# MCSPI2 register map
Vendor: Texas Instruments
Peripheral module from a debugger description file (folder omap4460).
Registers are 32-bit, read-write, reset 0x0 unless marked. A register's access mark holds for its fields unless they carry their own. Offsets are as the file gives them; lines under a group give offsets from that group; [hi:lo] are bit positions; {n}, {i} and the like mark numbered series; 'fields as' and 'values as' point back to an identical list; <NAME> marks a mode.

## MCSPI2
0x00 MCSPI_HL_REV ro reset not defined — IP Revision Identifier (X.Y.R) Used by software to track features, bugs, and compatibility
  [31:0] REVISION — IP Revision
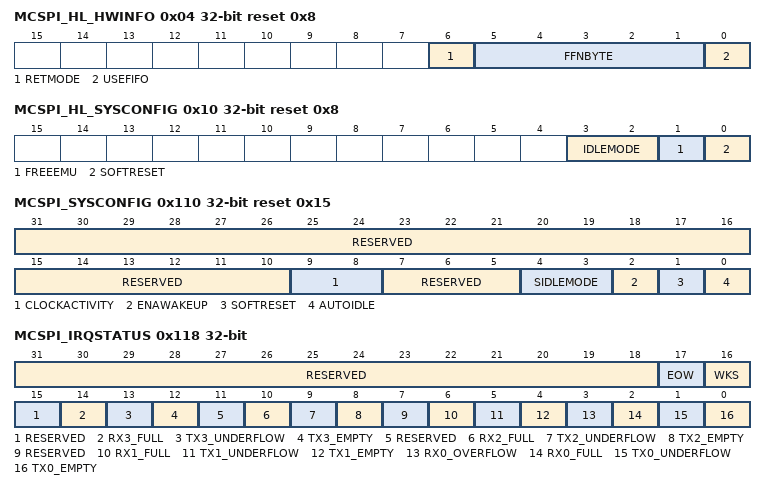
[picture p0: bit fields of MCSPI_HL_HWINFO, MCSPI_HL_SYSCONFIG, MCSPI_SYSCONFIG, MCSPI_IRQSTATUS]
0x04 MCSPI_HL_HWINFO ro reset 0x8 (reset mask 0xFFFFFFBF) — Information about the IP module's hardware configuration, that is, typically the module's HDL generics (if any). Actual field format and encoding is up to the module's designer to decide.
  [6] RETMODE — Retention Mode generic parameter. This bit field indicates whether the retention mode is supported using the pin PIRFFRET. 0x0: Retention mode disabled 0x1: Retention mode enabled
  [5:1] FFNBYTE — FIFO number of byte generic parameter This register defines the value of FFNBYTE generic parameter, only MSB bits from 8 down to 4 are taken into account.
    1=FFNBYTE_1_r (FIFO 16 bytes depth); 2=FFNBYTE_2_r (FIFO 32 bytes depth); 4=FFNBYTE_4_r (FIFO 64 bytes depth); 8=FFNBYTE_8_r (FIFO 128 bytes depth); 16=FFNBYTE_16_r (FIFO 256 bytes depth)
  [0] USEFIFO — Use of a FIFO enable: This bit indicates if a FIFO is integrated within controller design with its management.
    0=USEFIFO_0_r (FIFO not implemented in design); 1=USEFIFO_1_r (FIFO and its management implemented in design with depth defined by FFNBYTE generic)
0x10 MCSPI_HL_SYSCONFIG access per field reset 0x8 — Clock management configuration
  [3:2] IDLEMODE rw — Configuration of the local target state management mode. By definition, target can handle read/write transaction as long as it is out of IDLE state.
    0=Force-idle mode: local target's IDLE state follows (acknowledges) the system's idle requests unconditionally, that is, regardless of the IP module's internal requirements. Backup mode, for debug only.; 1=No-idle mode: local target never enters IDLE state. Backup mode, for debug only.; 2=Smart-idle mode: local target's IDLE state eventually follows (acknowledges) the system's idle requests, depending on the IP module's internal requirements. IP module shall not generate (IRQ- or DMA-request-related) wake-up events.; 3=Smart-idle wake-up-capable mode: local target's IDLE state eventually follows (acknowledges) the system's idle requests, depending on the IP module's internal requirements. IP module may generate (IRQ- or DMA-request-related) wake-up events when in IDLE state. Mode is relevant only if the appropriate IP module 'swake-up' output(s) is (are) implemented.
  [1] FREEEMU rw — Sensitivity to emulation (debug) suspend input signal.
    0=IP module is sensitive to emulation suspend; 1=IP module is not sensitive to emulation suspend
  [0] SOFTRESET rw — Software reset. (Optional)
    0=SOFTRESET_0_w (No action); 0=SOFTRESET_0_r (Reset done, no pending action); 1=SOFTRESET_1_r (Reset (software or other) ongoing); 1=SOFTRESET_1_w (Initiate software reset)
0x100 MCSPI_REVISION ro reset not defined — This register contains the revision number.
  [31:0] REVISION — IP revision
0x110 MCSPI_SYSCONFIG reset 0x15 — This register allows controlling various parameters of the OCP interface.
  [31:10] RESERVED — Reads returns 0
  [9:8] CLOCKACTIVITY — Clocks activity during wake-up mode period
    0=OCP and functional clocks may be switched off; 1=OCP clock is maintained. Functional clock may be switched off.; 2=Functional clock is maintained. OCP clock may be switched off.; 3=OCP and functional clocks are maintained
  [7:5] RESERVED — Reads returns 0
  [4:3] SIDLEMODE — Power management
    0=If an idle request is detected, the McSPI acknowledges it unconditionally and goes in inactive mode. Interrupt, DMA requests and wake-up lines are unconditionally deasserted and the module wake-up capability is deactivated even if the[EnaWakeUp] bit is set.; 1=If an idle request is detected, the request is ignored and the module does not switch to wake-up mode, and keeps on behaving normally; 2=If an idle request is detected, the module will switch to wake-up mode based on its internal activity, and the wake-up capability can be used if the bit[EnaWakeUp] is set; 3=Reserved - do not use
  [2] ENAWAKEUP — Wake-up feature control
    0=Wake-up capability is disabled; 1=Wake-up capability is enabled
  [1] SOFTRESET — Software reset. During reads it always returns 0.
    0=(write) Normal mode; 1=(write) Set this bit to 1 to trigger a module reset. The bit is automatically reset by the hardware.
  [0] AUTOIDLE — Internal OCP clock-gating strategy
    0=OCP clock is free-running; 1=Automatic OCP clock gating strategy is applied, based on the OCP interface activity
0x114 MCSPI_SYSSTATUS ro — This register provides status information about the module excluding the interrupt status information.
  [0] RESETDONE — Internal reset monitoring
    0=RESETDONE_0_r (Internal module reset is ongoing); 1=RESETDONE_1_r (Reset completed)
0x118 MCSPI_IRQSTATUS access not given — The interrupt status regroups all the status of the module internal events that can generate an interrupt.
  [31:18] RESERVED rw — Reads returns 0
  [17] EOW — End of word count event when a channel is enabled using the FIFO buffer and the channel had sent the number of SPI word defined byMCSPI_XFERLEVEL[WCNT]. (access RW W1toClr)
    0=EOW_0_w (w:Event status bit unchanged); 0=EOW_0_r (r: Event false); 1=EOW_1_r (r: Event is pending); 1=EOW_1_w (w:Event status bit is reset)
  [16] WKS — Wake-up event in slave mode when an active control signal is detected on the SPIEN line programmed in the field MCSPI_CH0CONF[SPIENSLV] (access RW W1toClr)
    0=WKS_0_r (r: Event false); 0=WKS_0_w (w:Event status bit unchanged); 1=WKS_1_w (w:Event status bit is reset); 1=WKS_1_r (r: Event is pending)
  [15] RESERVED rw — Reads returns 0
  [14] RX3_FULL — Receiver register is full or almost full. Only when Channel 3 is enabled (access RW W1toClr)
    0=RX3_FULL_0_r (r: Event false); 0=RX3_FULL_0_w (w:Event status bit unchanged); 1=RX3_FULL_1_w (w:Event status bit is reset); 1=RX3_FULL_1_r (r: Event is pending)
  [13] TX3_UNDERFLOW — Transmitter register underflow. Only when Channel 3 is enabled. The transmitter register is empty (not updated by host or DMA with new data) before its time slot assignment. Exception: No TX_underflow event when no data has been loaded into the transmitter register since channel has been enabled. (access RW W1toClr)
    0=TX3_UNDERFLOW_0_r (r: Event false); 0=TX3_UNDERFLOW_0_w (w:Event status bit unchanged); 1=TX3_UNDERFLOW_1_w (w:Event status bit is reset); 1=TX3_UNDERFLOW_1_r (r: Event is pending)
  [12] TX3_EMPTY — Transmitter register is empty or almost empty. Note: Enabling the channel automatically rises this event. (access RW W1toClr)
    0=TX3_EMPTY_0_r (r: Event false); 0=TX3_EMPTY_0_w (w:Event status bit unchanged); 1=TX3_EMPTY_1_w (w:Event status bit is reset); 1=TX3_EMPTY_1_r (r: Event is pending)
  [11] RESERVED rw — Reads returns 0.
  [10] RX2_FULL — Receiver register full or almost full. Channel 2 (access RW W1toClr)
    0=RX2_FULL_0_r (r: Event false); 0=RX2_FULL_0_w (w:Event status bit unchanged); 1=RX2_FULL_1_w (w:Event status bit is reset); 1=RX2_FULL_1_r (r: Event is pending)
  [9] TX2_UNDERFLOW — Transmitter register underflow. Channel 2 (access RW W1toClr)
    0=TX2_UNDERFLOW_0_r (r: Event false); 0=TX2_UNDERFLOW_0_w (w:Event status bit unchanged); 1=TX2_UNDERFLOW_1_w (w:Event status bit is reset); 1=TX2_UNDERFLOW_1_r (r: Event is pending)
  [8] TX2_EMPTY — Transmitter register empty or almost empty. Channel 2 (access RW W1toClr)
    0=TX2_EMPTY_0_r (r: Event false); 0=TX2_EMPTY_0_w (w:Event status bit unchanged); 1=TX2_EMPTY_1_w (w:Event status bit is reset); 1=TX2_EMPTY_1_r (r: Event is pending)
  [7] RESERVED rw — Reads returns 0
  [6] RX1_FULL — Receiver register full or almost full. Channel 1 (access RW W1toClr)
    0=RX1_FULL_0_r (r: Event false); 0=RX1_FULL_0_w (w:Event status bit unchanged); 1=RX1_FULL_1_w (w:Event status bit is reset); 1=RX1_FULL_1_r (r: Event is pending)
  [5] TX1_UNDERFLOW — Transmitter register underflow. Channel 1 (access RW W1toClr)
    0=TX1_UNDERFLOW_0_r (r: Event false); 0=TX1_UNDERFLOW_0_w (w:Event status bit unchanged); 1=TX1_UNDERFLOW_1_w (w:Event status bit is reset); 1=TX1_UNDERFLOW_1_r (r: Event is pending)
  [4] TX1_EMPTY — Transmitter register empty or almost empty. Channel 1 (access RW W1toClr)
    0=TX1_EMPTY_0_r (r: Event false); 0=TX1_EMPTY_0_w (w:Event status bit unchanged); 1=TX1_EMPTY_1_w (w:Event status bit is reset); 1=TX1_EMPTY_1_r (r: Event is pending)
  [3] RX0_OVERFLOW — Receiver register overflow (slave mode only). Channel 0 (access RW W1toClr)
    0=RX0_OVERFLOW_0_r (r: Event false); 0=RX0_OVERFLOW_0_w (w:Event status bit unchanged); 1=RX0_OVERFLOW_1_w (w:Event status bit is reset); 1=RX0_OVERFLOW_1_r (r: Event is pending)
  [2] RX0_FULL — Receiver register full or almost full. Channel 0 (access RW W1toClr)
    0=RX0_FULL_0_r (r: Event false); 0=RX0_FULL_0_w (w:Event status bit unchanged); 1=RX0_FULL_1_w (w:Event status bit is reset); 1=RX0_FULL_1_r (r: Event is pending)
  [1] TX0_UNDERFLOW — Transmitter register underflow. Channel 0 (access RW W1toClr)
    0=TX0_UNDERFLOW_0_r (r: Event false); 0=TX0_UNDERFLOW_0_w (w:Event status bit unchanged); 1=TX0_UNDERFLOW_1_w (w:Event status bit is reset); 1=TX0_UNDERFLOW_1_r (r: Event is pending)
  [0] TX0_EMPTY — Transmitter register empty or almost empty. Channel 0 (access RW W1toClr)
    0=TX0_EMPTY_0_r (r: Event false); 0=TX0_EMPTY_0_w (w:Event status bit unchanged); 1=TX0_EMPTY_1_w (w:Event status bit is reset); 1=TX0_EMPTY_1_r (r: Event is pending)
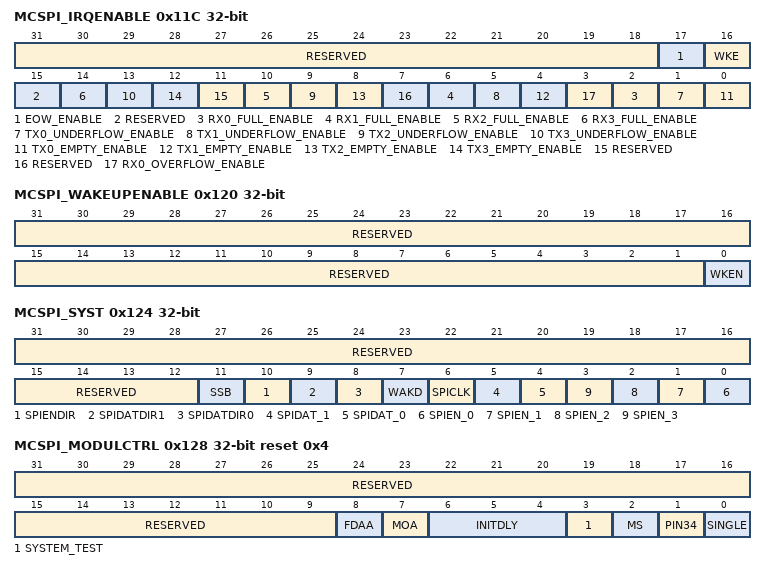
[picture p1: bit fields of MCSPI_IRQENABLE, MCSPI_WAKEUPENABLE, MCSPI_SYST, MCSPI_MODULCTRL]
0x11C MCSPI_IRQENABLE — This register allows enabling/disabling of the module internal sources of interrupt, on an event-by-event basis.
  [31:18] RESERVED — Reads return 0.
  [17] EOW_ENABLE — End of Word count Interrupt Enable.
    0=Interrupt disabled; 1=Interrupt enabled
  [16] WKE — Wake-up event interrupt enable in slave mode when an active control signal is detected on the SPIEN line programmed in the MCSPI_CH0CONF[SPIENSLV] bit
    0=Interrupt disabled; 1=Interrupt enabled
  [15] RESERVED — Reads returns 0.
  [4n+2] RX{n}_FULL_ENABLE (n=0..3) — Receiver register Full Interrupt Enable. Channel {n}
    0=Interrupt disabled; 1=Interrupt enabled
  [4n+1] TX{n}_UNDERFLOW_ENABLE (n=0..3) — Transmitter register Underflow Interrupt Enable. Channel {n}
    0=Interrupt disabled; 1=Interrupt enabled
  [4n] TX{n}_EMPTY_ENABLE (n=0..3) — Transmitter register Empty Interrupt Enable. Channel {n}
    0=Interrupt disabled; 1=Interrupt enabled
  [11] RESERVED — Reads return 0.
  [7] RESERVED — Reads return 0.
  [3] RX0_OVERFLOW_ENABLE — Receiver register Overflow Interrupt Enable. Channel 0
    0=Interrupt disabled; 1=Interrupt enabled
0x120 MCSPI_WAKEUPENABLE — The wake-up enable register allows enabling and disabling of the module internal sources of wakeup on event-by-event basis.
  [31:1] RESERVED — Reads returns 0.
  [0] WKEN — Wake-up functionality in slave mode when an active control signal is detected on the SPIEN line programmed in the MCSPI_CH0CONF[SPIENSLV] bit
    0=The event is not allowed to wake-up the system, even if the global control bit MCSPI_SYSCONF[EnaWakeUp] is set; 1=The event is allowed to wake-up the system if the global control bit MCSPI_SYSCONF[EnaWakeUp] is set
0x124 MCSPI_SYST — This register is used to check the correctness of the system interconnect either internally to peripheral bus, or externally to device I/O pads, when the module is configured in system test (SYSTEST) mode.
  [31:12] RESERVED — Reads returns 0.
  [11] SSB — Set status bit
    0=No action. Writing 0 does not clear already set status bits. This bit must be cleared before trying to clear a status bit of the <> register.; 1=Force to 1 all status bits of register. Writing 1 into this bit sets to 1 all status bits in the <> register.
  [10] SPIENDIR — Set the direction of the SPIEN[3:0] lines and SPICLK line.
    0=Output (as in master mode); 1=Input (as in slave mode)
  [9] SPIDATDIR1 — Set the direction of the SPIDAT[1].
    0=Output; 1=Input
  [8] SPIDATDIR0 — Set the direction of the SPIDAT[0].
    0=Output; 1=Input
  [7] WAKD — SWAKEUP output (signal data value of internal signal to system). The signal is driven high or low according to the value written into this register bit.
    0=The pin is driven low; 1=The pin is driven high
  [6] SPICLK — SPICLK line (signal data value) If MCSPI_SYST[SPIENDIR] = 1 (input mode direction), this bit returns the value on the CLKSPI line (high or low), and a write into this bit has no effect. If MCSPI_SYST[SPIENDIR] = 0 (output mode direction), the CLKSPI line is driven high or low according to the value written into this register.
  [5] SPIDAT_1 — SPIDAT[1] line (signal data value) If MCSPI_SYST[SPIDATDIR1] = 0 (output mode direction), the SPIDAT[1] line is driven high or low according to the value written into this register. If MCSPI_SYST[SPIDATDIR1] = 1 (input mode direction), this bit returns the value on the SPIDAT[1] line (high or low), and a write into this bit has no effect.
  [4] SPIDAT_0 — SPIDAT[0] line (signal data value) If MCSPI_SYST[SPIDATDIR0] = 0 (output mode direction), the SPIDAT[0] line is driven high or low according to the value written into this register. If MCSPI_SYST[SPIDATDIR0] = 1 (input mode direction), this bit returns the value on the SPIDAT[0] line (high or low), and a write into this bit has no effect.
  [n] SPIEN_{n} (n=0..3) — SPIEN[{n}] line (signal data value) If MCSPI_SYST[SPIENDIR] = 0 (output mode direction), the SPIENT[{n}] line is driven high or low according to the value written into this register. If MCSPI_SYST[SPIENDIR] = 1 (input mode direction), this bit returns the value on the SPIEN[{n}] line (high or low), and a write into this bit has no effect.
0x128 MCSPI_MODULCTRL reset 0x4 — This register is dedicated to the configuration of the serial port interface.
  [31:9] RESERVED — Reads returns 0.
  [8] FDAA — FIFO DMA address 256-bit aligned This register is used when a FIFO is managed by the module and DMA connected to the controller provides only 256-bit aligned address. If this bit is set the enabled channel which uses the FIFO has its data managed through MCSPI_DAFTX and MCSPI_DAFRX registers instead of MCSPI_TX(i) and MCSPI_RX(i) registers.
    0=FIFO data managed by MCSPI_TX(i) and MCSPI_RX(i) registers; 1=FIFO data managed by MCSPI_DAFTX and MCSPI_DAFRX registers
  [7] MOA — Multiple word OCP access: This register can only be used when a channel is enabled using a FIFO. It allows the system to perform multiple SPI word access for a single 32-bit OCP word access. This is possible for WL &lt; 16.
    0=Multiple word access disabled; 1=Multiple word access enabled with FIFO
  [6:4] INITDLY — Initial SPI delay for first transfer: This register is an option only available in SINGLE master mode. The controller waits for a delay to transmit the first SPI word after channel enabled and corresponding TX register filled. This delay is based on SPI output frequency clock. No clock output provided to the boundary and chip select is not active in 4-pin mode within this period.
    0=No delay for first spi transfer; 1=The controller wait 4 SPI bus clock; 2=The controller wait 8 SPI bus clock; 3=The controller wait 16 SPI bus clock; 4=The controller wait 32 SPI bus clock
  [3] SYSTEM_TEST — Enables the system test mode
    0=Functional mode; 1=System test mode (SYSTEST)
  [2] MS — Master/slave
    0=Master - The module generates the SPICLK and SPIEN[3:0]; 1=Slave - The module receives the SPICLK and SPIEN[3:0]
  [1] PIN34 — Pin mode selection: This register is used to configure the SPI pin mode, in master or slave mode. If asserted the controller only use SIMO, SOMI, and SPICLK clock pin for SPI transfers.
    0=SPIEN is used as a chip-select; 1=SPIEN is not used. In this mode all related options to chip-select have no meaning.
  [0] SINGLE — Single channel/Multi Channel (master mode only)
    0=More than one channel will be used in master mode; 1=Only one channel will be used in master mode. This bit must be set in Force SPIEN mode.
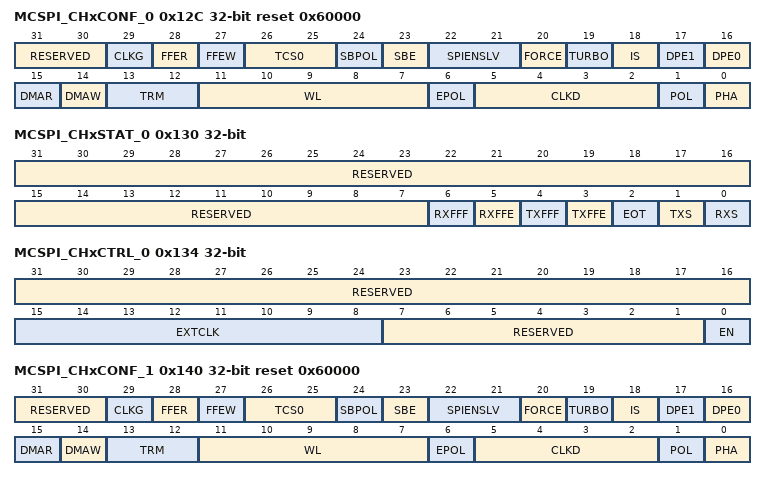
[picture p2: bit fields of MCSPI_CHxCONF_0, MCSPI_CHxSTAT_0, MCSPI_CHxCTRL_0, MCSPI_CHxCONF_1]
0x12C MCSPI_CHxCONF_0 access per field reset 0x60000 — This register is dedicated to the configuration of the channel 0
  [31:30] RESERVED ro — Read returns 0.
  [29] CLKG rw — Clock divider granularity This register defines the granularity of channel clock divider: power of 2 or one clock cycle granularity. When this bit is set the register MCSPI_CHCTRL[EXTCLK] must be configured to reach a maximum of 4096 clock divider ratio. Then the clock divider ratio is a concatenation of MCSPI_CHCONF[CLKD] and MCSPI_CHCTRL[EXTCLK] values
    0=Clock granularity of power of 2; 1=One clock cycle granularity
  [28] FFER rw — FIFO enabled for receive: Only one channel can have this bit field set.
    0=The buffer is not used to receive data; 1=The buffer is used to receive data
  [27] FFEW rw — FIFO enabled for transmit: Only one channel can have this bit field set.
    0=The buffer is not used to transmit data; 1=The buffer is used to transmit data
  [26:25] TCS0 rw — Chip-select time control This 2-bit field defines the number of interface clock cycles between CS toggling and first or last edge of SPI clock.
    0=0.5 clock cycle; 1=1.5 clock cycles; 2=2.5 clock cycles; 3=3.5 clock cycles
  [24] SBPOL rw — Start-bit polarity
    0=Start-bit polarity is held to 0 during SPI transfer; 1=Start-bit polarity is held to 1 during SPI transfer
  [23] SBE rw — Start-bit enable for SPI transfer
    0=Default SPI transfer length as specified by WL bit field; 1=Start bit D/CX added before SPI transfer polarity is defined by MCSPI_CH0CONF[SBPOL]
  [22:21] SPIENSLV rw — Channel 0 only and slave mode only: SPI slave select signal detection. Reserved bits for other cases.
    {v}=Detection enabled only on SPIEN[{v}] (v=0..3)
  [20] FORCE rw — Manual SPIEN assertion to keep SPIEN active between SPI words (single channel master mode only).
    0=Writing 0 into this bit drives low the SPIEN line when MCSPI_CHCONF(i)[EPOL]=0, and drives it high when MCSPI_CHCONF(i)[EPOL]=1; 1=Writing 1 into this bit drives high the SPIEN line when MCSPI_CHCONF(i)[EPOL]=0, and drives it low when MCSPI_CHCONF(i)[EPOL]=1
  [19] TURBO rw — Turbo mode
    0=Turbo is deactivated (recommended for single SPI word transfer); 1=Turbo is activated to maximize the throughput for multiple SPI words transfer
  [18] IS rw — Input Select
    0=Data line 0 (SPIDAT[0]) selected for reception; 1=Data line 1 (SPIDAT[1]) selected for reception
  [17] DPE1 rw — Transmission enable for data line 1 (SPIDATAGZEN[1])
    0=Data line 1 (SPIDAT[1]) selected for transmission; 1=No transmission on Data Line1 (SPIDAT[1])
  [16] DPE0 rw — Transmission Enable for data line 0 (SPIDATAGZEN[0])
    0=Data Line0 (SPIDAT[0]) selected for transmission; 1=No transmission on data line 0 (SPIDAT[0])
  [15] DMAR rw — DMA read request The DMA read request line is asserted when the channel is enabled and a new data is available in the receive register of the channel. The DMA read request line is deasserted on read completion of the receive register of the channel.
    0=DMA read request disabled; 1=DMA read request enabled
  [14] DMAW rw — DMA write request. The DMA write request line is asserted when The channel is enabled and the transmitter register of the channel is empty. The DMA write request line is deasserted on load completion of the transmitter register of the channel.
    0=DMA write request disabled; 1=DMA write request enabled
  [13:12] TRM rw — Transmit/receive modes
    0=Transmit-and-receive mode; 1=Receive-only mode; 2=Transmit-only mode
  [11:7] WL rw — SPI word length
    {v}=The SPI word is {v+1} bits long (v=3..31)
  [6] EPOL rw — SPIEN polarity
    0=SPIEN is held high during the ACTIVE state; 1=SPIEN is held low during the ACTIVE state
  [5:2] CLKD rw — Frequency divider for SPICLK (only when the module is a Master SPI device). A programmable clock divider divides the SPI reference clock (CLKSPIREF) with a 4-bit value, and results in a new clock SPICLK available to shift-in and shift-out data. By default the clock divider ratio has a power of 2 granularity when MCSPI_CHCONF[CLKG] is cleared. Otherwise this register is the 4-LSB bit of a 12-bit register concatenated with clock divider extension MCSPI_CHCTRL[EXTCLK] register. The value description below defines the clock ratio when MCSPI_CHCONF[CLKG] is set to 0.
    0=1; 1=2; 2=4; 3=8; 4=16; 5=32; 6=64; 7=128; 8=256; 9=512; 10=1024; 11=2048; 12=4096; 13=8192; 14=16384; 15=32768
  [1] POL rw — SPICLK polarity
    0=SPICLK is held high during the ACTIVE state; 1=SPICLK is held low during the ACTIVE state
  [0] PHA rw — SPICLK phase
    0=Data are latched on odd-numbered edges of SPICLK; 1=Data are latched on even-numbered edges of SPICLK
0x130 MCSPI_CHxSTAT_0 ro — This register provides status information about transmitter and receiver registers of channel 0.
  [31:7] RESERVED — Read returns 0.
  [6] RXFFF — Channel 'i' FIFO receive buffer full status
    0=RXFFF_0_r (FIFO receive buffer is not full); 1=RXFFF_1_r (FIFO receive buffer is full)
  [5] RXFFE — Channel 'i' FIFO receive buffer empty status
    0=RXFFE_0_r (FIFO receive buffer is not empty); 1=RXFFE_1_r (FIFO receive buffer is empty)
  [4] TXFFF — Channel 'i' FIFO transmit buffer full status
    0=TXFFF_0_r (FIFO transmit buffer is not full); 1=TXFFF_1_r (FIFO transmit buffer is full)
  [3] TXFFE — Channel 'i' FIFO transmit buffer empty status
    0=TXFFE_0_r (FIFO transmit buffer is not empty); 1=TXFFE_1_r (FIFO transmit buffer is empty)
  [2] EOT — Channel 'i' end of transfer status. The definitions of beginning and end of transfer vary with master versus slave and the transfer format (transmit/receive modes, turbo mode). See dedicated chapters for details.
    0=EOT_0_r (This flag is automatically cleared when the shift register is loaded with the data from the transmitter register (beginning of transfer).); 1=EOT_1_r (This flag is automatically set to one at the end of an SPI transfer.)
  [1] TXS — Channel 'i' transmitter register status
    0=TXS_0_r (Register is full.); 1=TXS_1_r (Register is empty.)
  [0] RXS — Channel 'i' receiver register status
    0=RXS_0_r (Register is empty.); 1=RXS_1_r (Register is full.)
0x134 MCSPI_CHxCTRL_0 — This register is dedicated to enable channel 0.
  [31:16] RESERVED — Read returns 0.
  [15:8] EXTCLK — Clock ratio extension: This register is used to concatenate with MCSPI_CHCONF[CLKD] register for clock ratio only when granularity is one clock cycle (MCSPI_CHCONF[CLKG] set to 1). Then the maximum value reached is 4096 clock divider ratio.
    0=Clock ratio is CLKD + 1; 1=Clock ratio is CLKD + 1 + 16; 255=Clock ratio is CLKD + 1 + 4080
  [7:1] RESERVED — Read returns 0.
  [0] EN — Channel enable
    0=Channel 'i' is not active; 1=Channel 'i' is active
0x138 MCSPI_TXx_0 — This register contains a single SPI word to transmit on the serial link, what ever SPI word length is.
  [31:0] TDATA — Channel 0 data to transmit
0x13C MCSPI_RXx_0 ro — This register contains a single SPI word received through the serial link, what ever SPI word length is.
  [31:0] RDATA — Channel 0 received data
0x140 MCSPI_CHxCONF_1 access per field reset 0x60000 — This register is dedicated to the configuration of the channel 0
  fields as MCSPI_CHxCONF_0
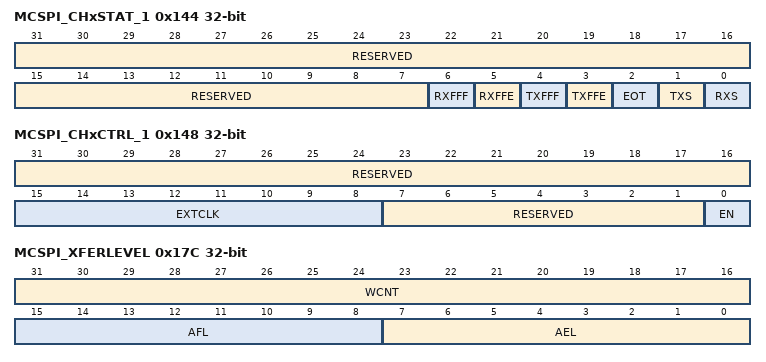
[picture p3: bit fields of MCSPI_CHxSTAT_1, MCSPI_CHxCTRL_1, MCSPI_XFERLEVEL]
0x144 MCSPI_CHxSTAT_1 ro — This register provides status information about transmitter and receiver registers of channel 0.
  fields as MCSPI_CHxSTAT_0
0x148 MCSPI_CHxCTRL_1 — This register is dedicated to enable channel 0.
  fields as MCSPI_CHxCTRL_0
0x14C MCSPI_TXx_1 — This register contains a single SPI word to transmit on the serial link, what ever SPI word length is.
  [31:0] TDATA — Channel 0 data to transmit
0x150 MCSPI_RXx_1 ro — This register contains a single SPI word received through the serial link, what ever SPI word length is.
  [31:0] RDATA — Channel 0 received data
0x17C MCSPI_XFERLEVEL — This register provides transfer levels needed while using FIFO buffer during transfer.
  [31:16] WCNT — SPI word counter. This register holds the programmable value of number of SPI word to be transferred on channel which is using the FIFO buffer. When transfer had started, a read back in this register returns the current SPI word transfer index.
    0=Counter not used; 1=One word; 0xFFFE=65534 SPI word; 0xFFFF=65535 SPI word
  [15:8] AFL — Buffer almost full This register holds the programmable almost full level value used to determine almost full buffer condition. If the user wants an interrupt or a DMA read request to be issued during a receive operation when the data buffer holds at least n bytes, then the buffer MCSPI_MODULCTRL[AFL] must be set with n–1.The size of this register is defined by the generic parameter FFNBYTE.
    0=1 byte; 1=2 bytes; 254=255bytes; 255=256bytes
  [7:0] AEL — Buffer almost empty. This register holds the programmable almost empty level value used to determine almost empty buffer condition. If the user wants an interrupt or a DMA write request to be issued during a transmit operation when the data buffer is able to receive n bytes, then the bufferMCSPI_MODULCTRL[AEL] must be set with – 1.
    0=1 byte; 1=2 bytes; 254=255 bytes; 255=256bytes
